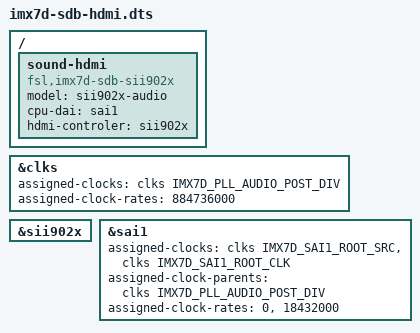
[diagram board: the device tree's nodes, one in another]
/*
 * Copyright (C) 2015 Freescale Semiconductor, Inc.
 *
 * This program is free software; you can redistribute it and/or modify
 * it under the terms of the GNU General Public License version 2 as
 * published by the Free Software Foundation.
 */

#include "imx7d-sdb.dts"

/ {
	sound-hdmi {
		compatible = "fsl,imx7d-sdb-sii902x",
			   "fsl,imx-audio-sii902x";
		model = "sii902x-audio";
		cpu-dai = <&sai1>;
		hdmi-controler = <&sii902x>;
	};
};

&clks {
	assigned-clocks = <&clks IMX7D_PLL_AUDIO_POST_DIV>;
	assigned-clock-rates = <884736000>;
};

&sii902x {
	status = "okay";
};

&sai1 {
	assigned-clocks = <&clks IMX7D_SAI1_ROOT_SRC>,
			  <&clks IMX7D_SAI1_ROOT_CLK>;
	assigned-clock-parents = <&clks IMX7D_PLL_AUDIO_POST_DIV>;
	assigned-clock-rates = <0>, <18432000>;
	status = "okay";
};
